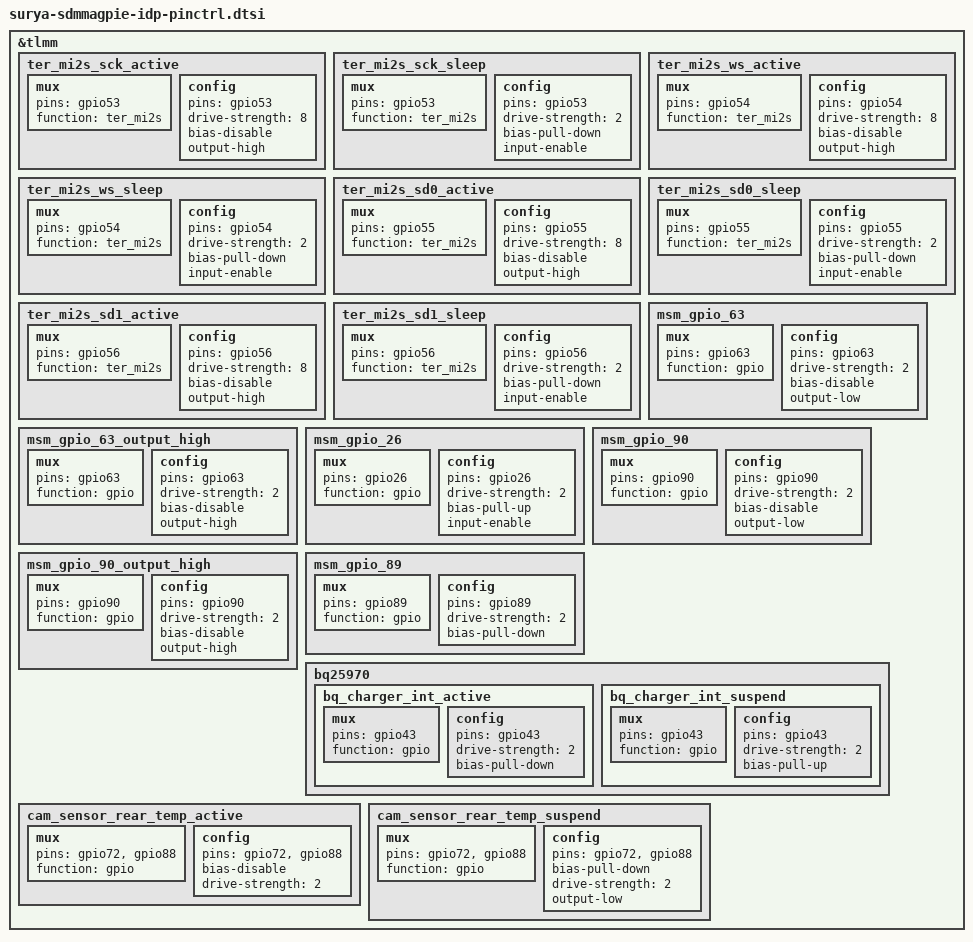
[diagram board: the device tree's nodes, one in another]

&tlmm {

	ter_mi2s_sck_active: ter_mi2s_sck_active {
 		mux {
 			pins = "gpio53";
 			function = "ter_mi2s";
 		};

		config {
 			pins = "gpio53";
 			drive-strength = <8>;
 			bias-disable;
 			output-high;
 		};
 	};
 
 	ter_mi2s_sck_sleep: ter_mi2s_sck_sleep {
 		mux {
 			pins = "gpio53";
 			function = "ter_mi2s";
 		};
 
 		config {
 			pins = "gpio53";
 			drive-strength = <2>;   
 			bias-pull-down;         
 			input-enable;

		};
 	};
 
 	ter_mi2s_ws_active: ter_mi2s_ws_active {
 		mux {
 			pins = "gpio54";
 			function = "ter_mi2s";
 		};
 
 		config {
 			pins = "gpio54";
 			drive-strength = <8>;
 			bias-disable;           
 			output-high;
 		};
 	};
 
 	ter_mi2s_ws_sleep: ter_mi2s_ws_sleep {
 		mux {
 			pins = "gpio54";
 			function = "ter_mi2s";
 		};
 
 		config {
 			pins = "gpio54";
 			drive-strength = <2>;
 			bias-pull-down;         
 			input-enable;
 		};
 	};
 
 	ter_mi2s_sd0_active: ter_mi2s_sd0_active {
 		mux {
 			pins = "gpio55";
 			function = "ter_mi2s";
 		};
 
 		config {
 			pins = "gpio55";
 			drive-strength = <8>;
 			bias-disable;           
 			output-high;
 		};
 	};
 
 	ter_mi2s_sd0_sleep: ter_mi2s_sd0_sleep {
 		mux {
 			pins = "gpio55";
 			function = "ter_mi2s";
 		};
 
 		config {
 			pins = "gpio55";
 			drive-strength = <2>;
 			bias-pull-down;         
 			input-enable;
 		};
 	};

	ter_mi2s_sd1_active: ter_mi2s_sd1_active {
 		mux {
 			pins = "gpio56";
 			function = "ter_mi2s";
 		};
 
 		config {
 			pins = "gpio56";
 			drive-strength = <8>;
 			bias-disable;           
 			output-high;
 		};
 	};
 
 	ter_mi2s_sd1_sleep: ter_mi2s_sd1_sleep {
 		mux {
 			pins = "gpio56";
 			function = "ter_mi2s";
 		};
 
 		config {
 			pins = "gpio56";
 			drive-strength = <2>;
 			bias-pull-down;         
 			input-enable;
 		};
	};

 	msm_gpio_63:msm_gpio_63 {
 		mux {
 			pins="gpio63";
 			function= "gpio";
 		};
 		config {
 			pins= "gpio63";
 			drive-strength = <2>;
 			bias-disable;
 			output-low;
 		};
 	};
 	msm_gpio_63_output_high:msm_gpio_63_output_high {
 		mux {
 			pins = "gpio63";
 			function = "gpio";
 		};
 		config {
 			pins = "gpio63";
 			drive-strength = <2>;
 			bias-disable;
 			output-high;
 		};
 	};
 	msm_gpio_26:msm_gpio_26 {
 		mux {
 			pins = "gpio26";
 			function = "gpio";
 		};
 		config {
 			pins = "gpio26";
 			drive-strength = <2>;
 			bias-pull-up;
 			input-enable;
 		};
 	};
 
 	msm_gpio_90:msm_gpio_90 {
 		mux {
 			pins="gpio90";
 			function= "gpio";
 		};
 		config {
 			pins= "gpio90";
 			drive-strength = <2>;
 			bias-disable;
 			output-low;
 		};
 	};
 
 	msm_gpio_90_output_high:msm_gpio_90_output_high {
 		mux {
 			pins = "gpio90";
 			function = "gpio";
 		};
 		config {
 			pins = "gpio90";
 			drive-strength = <2>;
 			bias-disable;
 			output-high;
 		};
 	};
 
 	msm_gpio_89:msm_gpio_89{
 		mux {
 			pins = "gpio89";
 			function = "gpio";
 		};
 		config {
 			pins = "gpio89";
 			drive-strength=<2>;
 			bias-pull-down;
 		};
 	};

 	bq25970{
 		bq_charger_int_active: bq_charger_int_active{
 			mux {
 				pins = "gpio43";
 				function = "gpio";
 			};
 
 			config {
 				pins = "gpio43";
 				drive-strength = <2>;
 			        bias-pull-down;
 			};
 		};
 		bq_charger_int_suspend: bq_charger_int_suspend {
 			mux {
 				pins = "gpio43";
 				function = "gpio";
 			};

				config {
 				pins = "gpio43";
 				drive-strength = <2>;
 				bias-pull-up;
 			};
 		};
 	};
 	cam_sensor_rear_temp_active:cam_sensor_rear_temp_active{
 		mux {
 			pins = "gpio72","gpio88";
 			function = "gpio";
 		};

		config {
 			pins = "gpio72","gpio88";
 			bias-disable;
 			drive-strength = <2>; 
 		};
 	};
 
 	cam_sensor_rear_temp_suspend:cam_sensor_rear_temp_suspend{
 		mux {
 			pins = "gpio72","gpio88";
 			function = "gpio";
 		};
 
 		config {
 			pins = "gpio72","gpio88";
 			bias-pull-down;
 			drive-strength = <2>; 
 			output-low;
 		};
 	};
 
/* 	
	cam_sensor_rear_active: cam_sensor_rear_active {
 		mux {
 			pins = "gpio25","gpio66";
 			function = "gpio";
 		};

 		config {
 			pins = "gpio25","gpio66";
 			bias-disable; 
 			drive-strength = <2>; 
 		};
 	};
 
 	cam_sensor_rear_suspend: cam_sensor_rear_suspend {
 		mux {
 			pins = "gpio25","gpio66";
 			function = "gpio";
 		};
 
 		config {
			pins = "gpio25","gpio66";
 			bias-pull-down; 
 			drive-strength = <2>; 
 			output-low;
 		};
 	};
 	//wide sensor reset end
 
 	cam_sensor_rear_depth_active:cam_sensor_rear_depth_active{
 		  mux {
 			  pins = "gpio93";
 			  function = "gpio";
 		  };
 		  config {
 			  pins = "gpio93";
 			  bias-disable;
 			  drive-strength = <2>; 
 		  };
 	  };
 	cam_sensor_rear_depth_suspend:cam_sensor_rear_depth_suspend{
 		  mux {
 			  pins = "gpio93";
 			  function = "gpio";
 		  };
 		  config {
 			  pins = "gpio93";
 			  bias-pull-down;
 			  drive-strength = <2>; 
 			  output-low;
 		  };
 	  };
 
 	cam_sensor_front_active: cam_sensor_front_active {
 		mux {
 			pins ="gpio23";
 			function = "gpio";
 		};

		config {
 			pins = "gpio23";
 			bias-disable; 
 			drive-strength = <2>; 
 		};
 	};
 
 	cam_sensor_front_suspend: cam_sensor_front_suspend {
 		mux {
 			pins =  "gpio23";
 			function = "gpio";
 		};
 
 		config {
 			pins =  "gpio23";
 			bias-pull-down; 
 			drive-strength = <2>; 
 			output-low;
 		};
 	};
 
 	cam_sensor_rear3_active: cam_sensor_rear3_active {
 		mux {
 			pins = "gpio24";
 			function = "gpio";
 		};
 
 		config {
 			pins = "gpio24";
 			bias-disable; 
 			drive-strength = <2>; 
 		};
 	};
 
 	cam_sensor_rear3_suspend: cam_sensor_rear3_suspend {
 		mux {
 			pins = "gpio24";
 			function = "gpio";
 		};
 
 		config {
 			pins = "gpio24";
 			bias-pull-down; 
 			drive-strength = <2>; 
 			output-low;
 		};
 	};
 
 	//micro sensor reset start
 	cam_sensor_rear_micro_active: cam_sensor_rear_micro_active {
 		mux {
 			pins = "gpio64", "gpio57";
 			function = "gpio";
 		};
 
 		config {
 			pins = "gpio64", "gpio57";
 			bias-disable;
 			drive-strength = <2>; 
 		};
 	};
 
 	cam_sensor_rear_micro_suspend: cam_sensor_rear_micro_suspend {
 		mux {
 			pins = "gpio64", "gpio57";
 			function = "gpio";
 		};
 
 		config {
 			pins = "gpio64", "gpio57";
 			bias-pull-down; 
 			drive-strength = <2>; 
 			output-low;
 		};
 	};
*/
};
